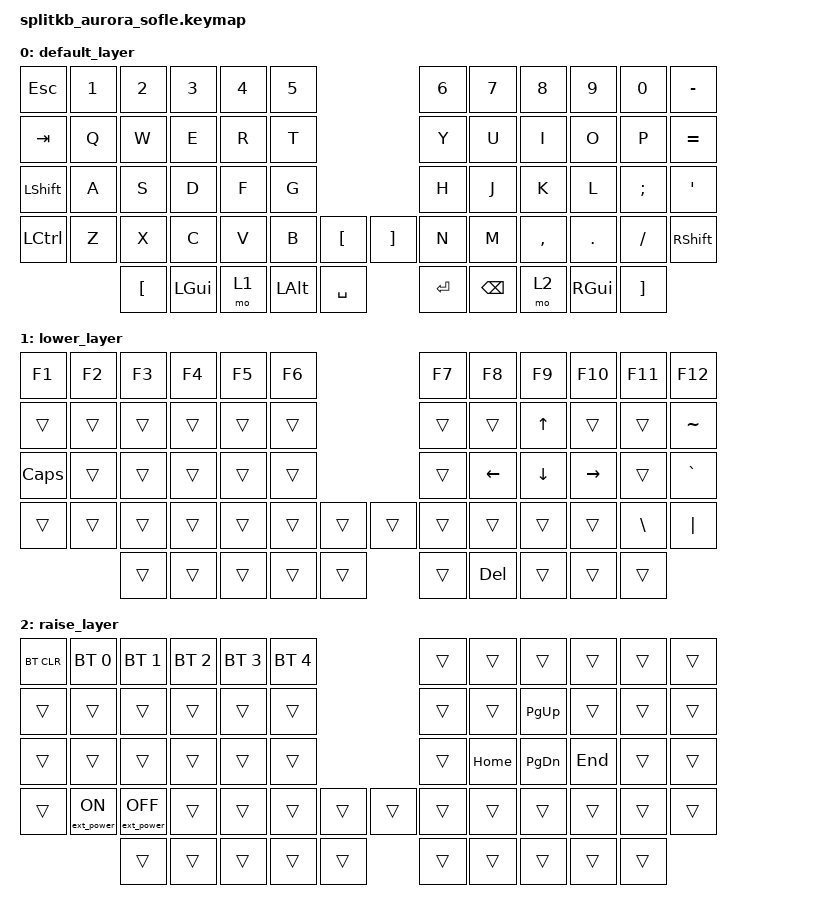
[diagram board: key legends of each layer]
/*
 * Copyright (c) 2023 The ZMK Contributors
 *
 * SPDX-License-Identifier: MIT
 */

#include <behaviors.dtsi>
#include <dt-bindings/zmk/keys.h>
#include <dt-bindings/zmk/bt.h>
#include <dt-bindings/zmk/ext_power.h>

/* Uncomment this block if using RGB
&led_strip {
    chain-length = <6>;
    // chain-length = <35>; // Uncomment if using both per-key and underglow LEDs
    // chain-length = <29>; // Uncomment if using only per-key LEDs.
};
 */

/ {
	keymap {
		compatible = "zmk,keymap";

		default_layer {
// ------------------------------------------------------------------------------------------------------------
// |  ESC  |  1  |  2  |  3   |  4   |  5   |                   |  6   |  7    |  8    |  9   |   0   |   -   |
// |  TAB  |  Q  |  W  |  E   |  R   |  T   |                   |  Y   |  U    |  I    |  O   |   P   |   =   |
// | SHIFT |  A  |  S  |  D   |  F   |  G   |                   |  H   |  J    |  K    |  L   |   ;   |   '   |
// |  CTRL |  Z  |  X  |  C   |  V   |  B   |   "["  |  |  "]"  |  N   |  M    |  ,    |  .   |   /   | SHIFT |
//               | "[" |  GUI |LOWER | ALT  |  SPACE |  | ENTER | BSPC | RAISE |  GUI  | "]" |
			bindings = <
&kp ESC   &kp N1 &kp N2 &kp N3   &kp N4   &kp N5                     &kp N6 &kp N7   &kp N8    &kp N9  &kp N0   &kp MINUS
&kp TAB   &kp Q  &kp W  &kp E    &kp R    &kp T                      &kp Y  &kp U    &kp I     &kp O   &kp P    &kp EQUAL
&kp LSHFT &kp A  &kp S  &kp D    &kp F    &kp G                      &kp H  &kp J    &kp K     &kp L   &kp SEMI &kp SQT
&kp LCTRL &kp Z  &kp X  &kp C    &kp V    &kp B  &kp LBKT   &kp RBKT &kp N  &kp M    &kp COMMA &kp DOT &kp FSLH &kp RSHFT
            	 &kp LBKT    &kp LGUI &mo 1   &kp LALT &kp SPACE  &kp RET  &kp BSPC  &mo 2  &kp RGUI &kp RBKT
			>;

			sensor-bindings = <&inc_dec_kp C_VOL_UP C_VOL_DN>;
		};

// Left button
		lower_layer {
// ------------------------------------------------------------------------------------------------------------
// |  F1   |  F2 |  F3 |  F4  |  F5  |  F6  |                   |  F7  |  F8   |  F9   |  F10 |  F11  |  F12  |
// |       |     |     |      |      |      |                   |      |       |  UP   |      |       |   ~   |
// |  CAPS |     |     |      |      |      |                   |      | LEFT  | DOWN  | RIGHT|       |   `   |
// |       |     |     |      |      |      |        |  |       |      |       |       |      |   \   |   |   |
//               |     |      |      |      |        |  |  DEL  |      |       |       |      |
			bindings = <

&kp F1     &kp F2           &kp F3            &kp F4            &kp F5       &kp F6                       &kp F7    &kp F8    &kp F9       &kp F10   &kp F11   &kp F12
&trans     &trans           &trans            &trans            &trans       &trans                       &trans    &trans    &kp UP       &trans    &trans    &kp TILDE
&kp CAPS   &trans           &trans            &trans            &trans       &trans                       &trans    &kp LEFT  &kp DOWN     &kp RIGHT &trans    &kp GRAVE
&trans     &trans           &trans            &trans            &trans       &trans    &trans   &trans    &trans    &trans    &trans       &trans    &kp BSLH  &kp PIPE
                            &trans		      &trans            &trans       &trans    &trans   &trans    &kp DEL   &trans    &trans	   &trans
			>;

			sensor-bindings = <&inc_dec_kp C_VOL_UP C_VOL_DN>;
		};

// Right button
		raise_layer {
// ------------------------------------------------------------------------------------------------------------
// | BTCLR | BT1 | BT2 |  BT3 |  BT4 |  BT5 |                   |      |       |       |      |       |      |
// |       |     |     |      |      |      |                   |      |       | PGUP  |      |       |      |
// |       |     |     |      |      |      |                   |      |  HOME |  PGDN |  END |       |      |
// |       |EP ON|EPOFF|      |      |      |                   |      |       |       |      |       |      |
//               |     |      |      |      |        |  |       |      |       |       |      |
			bindings = <
&bt BT_CLR &bt BT_SEL 0  &bt BT_SEL 1  &bt BT_SEL 2  &bt BT_SEL 3   &bt BT_SEL 4   &trans      &trans    &trans    &trans   &trans    &trans
&trans     &trans  &trans &trans  &trans  &trans                       &trans      &trans      &kp PG_UP    &trans   &trans    &trans
&trans     &trans  &trans &trans  &trans  &trans                       &trans      &kp HOME    &kp PG_DN    &kp END   &trans    &trans
&trans     &ext_power EP_ON  &ext_power EP_OFF &trans  &trans  &trans   &trans   &trans    &trans      &trans    &trans    &trans   &trans    &trans
                             &trans&trans  &trans  &trans    &trans   &trans    &trans      &trans    &trans    &trans
			>;

			sensor-bindings = <&inc_dec_kp C_VOL_UP C_VOL_DN>;
		};
	};
};
